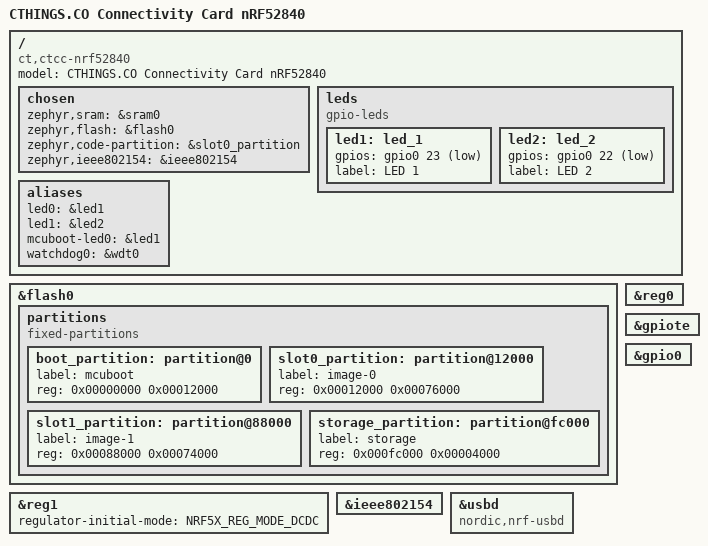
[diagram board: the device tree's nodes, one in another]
/*
 * Copyright (c) 2024 CTHINGS.CO
 *
 * SPDX-License-Identifier: Apache-2.0
 */

/dts-v1/;
#include <nordic/nrf52840_qiaa.dtsi>

/ {
	model = "CTHINGS.CO Connectivity Card nRF52840";
	compatible = "ct,ctcc-nrf52840";

	chosen {
		zephyr,sram = &sram0;
		zephyr,flash = &flash0;
		zephyr,code-partition = &slot0_partition;
		zephyr,ieee802154 = &ieee802154;
	};

	leds {
		compatible = "gpio-leds";

		led1: led_1 {
			gpios = <&gpio0 23 GPIO_ACTIVE_LOW>;
			label = "LED 1";
		};

		led2: led_2 {
			gpios = <&gpio0 22 GPIO_ACTIVE_LOW>;
			label = "LED 2";
		};
	};

	aliases {
		led0 = &led1;
		led1 = &led2;
		mcuboot-led0 = &led1;
		watchdog0 = &wdt0;
	};
};

&flash0 {
	partitions {
		compatible = "fixed-partitions";
		#address-cells = <1>;
		#size-cells = <1>;

		boot_partition: partition@0 {
			label = "mcuboot";
			reg = <0x00000000 0x00012000>;
		};

		slot0_partition: partition@12000 {
			label = "image-0";
			reg = <0x00012000 0x00076000>;
		};

		slot1_partition: partition@88000 {
			label = "image-1";
			reg = <0x00088000 0x00074000>;
		};

		storage_partition: partition@fc000 {
			label = "storage";
			reg = <0x000fc000 0x00004000>;
		};
	};
};

&reg0 {
	status = "okay";
};

&reg1 {
	regulator-initial-mode = <NRF5X_REG_MODE_DCDC>;
};

&gpiote {
	status = "okay";
};

&gpio0 {
	status = "okay";
};

&ieee802154 {
	status = "okay";
};

zephyr_udc0: &usbd {
	compatible = "nordic,nrf-usbd";
	status = "okay";
};

#include <../boards/common/usb/cdc_acm_serial.dtsi>
